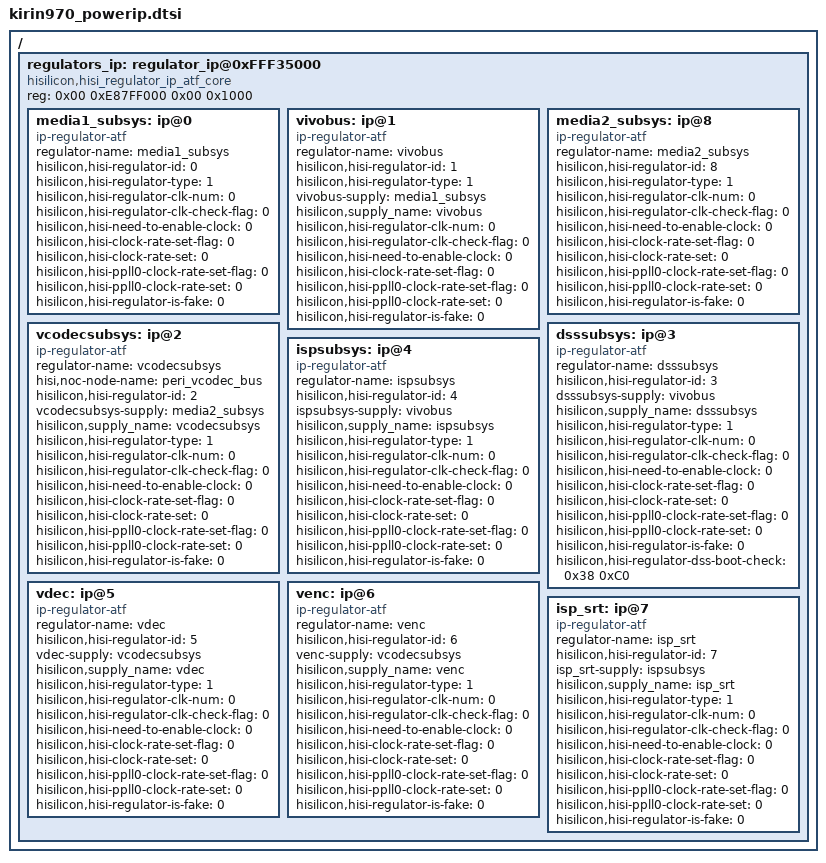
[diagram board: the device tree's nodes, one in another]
/*
 *  Copyright (C) 2012-2013 Linaro Ltd.
 *
 *  This program is free software; you can redistribute it and/or modify
 *  it under the terms of the GNU General Public License version 2 as
 *  publishhed by the Free Software Foundation.
 */

/{
	regulators_ip: regulator_ip@0xFFF35000 {
		compatible = "hisilicon,hisi_regulator_ip_atf_core";
		reg = <0x00 0xE87FF000 0x00 0x1000>;

		media1_subsys: ip@0 {
			compatible = "ip-regulator-atf";
			regulator-name = "media1_subsys";
			hisilicon,hisi-regulator-id = <0>;
			hisilicon,hisi-regulator-type = <1>;/*0:pmu;1:ip;2:scharger*/
			hisilicon,hisi-regulator-clk-num = <0>;
			hisilicon,hisi-regulator-clk-check-flag = <0>;/*0:not check clock state;1:check clock state*/
			hisilicon,hisi-need-to-enable-clock = <0>;/*0:donot enable clock;1:enable clock*/
			hisilicon,hisi-clock-rate-set-flag = <0>;/*low frequency clock set flag:0:donot set clock rate;1:set clock rate*/
			hisilicon,hisi-clock-rate-set = <0>;/*frequency:0:not set frequency;*/
			hisilicon,hisi-ppll0-clock-rate-set-flag = <0>;/*switch to ppll0 flag:0:donot set clock rate;1:set clock rate*/
			hisilicon,hisi-ppll0-clock-rate-set = <0>;/*ppll0 frequency:0:not set frequency;*/
			hisilicon,hisi-regulator-is-fake = <0>;/*0:this ip is effective;1:this ip is ineffective*/
		};
		vivobus: ip@1 {
			compatible = "ip-regulator-atf";
			regulator-name = "vivobus";
			hisilicon,hisi-regulator-id = <1>;
			hisilicon,hisi-regulator-type = <1>;/*0:pmu;1:ip;2:scharger*/
			vivobus-supply = <&media1_subsys>;
			hisilicon,supply_name = "vivobus";
			hisilicon,hisi-regulator-clk-num = <0>;
			hisilicon,hisi-regulator-clk-check-flag = <0>;/*0:not check clock state;1:check clock state*/
			hisilicon,hisi-need-to-enable-clock = <0>;/*0:donot enable clock;1:enable clock*/
			hisilicon,hisi-clock-rate-set-flag = <0>;/*low frequency clock set flag:0:donot set clock rate;1:set clock rate*/
			hisilicon,hisi-ppll0-clock-rate-set-flag = <0>;
			hisilicon,hisi-ppll0-clock-rate-set = <0>;
			hisilicon,hisi-regulator-is-fake = <0>;/*0:this ip is effective;1:this ip is ineffective*/
		};

		media2_subsys: ip@8 {
			compatible = "ip-regulator-atf";
			regulator-name = "media2_subsys";
			hisilicon,hisi-regulator-id = <8>;
			hisilicon,hisi-regulator-type = <1>;
			hisilicon,hisi-regulator-clk-num = <0>;
			hisilicon,hisi-regulator-clk-check-flag = <0>;
			hisilicon,hisi-need-to-enable-clock = <0>;
			hisilicon,hisi-clock-rate-set-flag = <0>;
			hisilicon,hisi-clock-rate-set = <0>;
			hisilicon,hisi-ppll0-clock-rate-set-flag = <0>;
			hisilicon,hisi-ppll0-clock-rate-set = <0>;
			hisilicon,hisi-regulator-is-fake = <0>;
		};

		vcodecsubsys: ip@2 {
			compatible = "ip-regulator-atf";
			regulator-name = "vcodecsubsys";
			hisi,noc-node-name = "peri_vcodec_bus";
			hisilicon,hisi-regulator-id = <2>;
			vcodecsubsys-supply = <&media2_subsys>;
			hisilicon,supply_name = "vcodecsubsys";
			hisilicon,hisi-regulator-type = <1>;
			hisilicon,hisi-regulator-clk-num = <0>;
			hisilicon,hisi-regulator-clk-check-flag = <0>;
			hisilicon,hisi-need-to-enable-clock = <0>;
			hisilicon,hisi-clock-rate-set-flag = <0>;
			hisilicon,hisi-clock-rate-set = <0>;
			hisilicon,hisi-ppll0-clock-rate-set-flag = <0>;
			hisilicon,hisi-ppll0-clock-rate-set = <0>;
			hisilicon,hisi-regulator-is-fake = <0>;
		};
		dsssubsys: ip@3 {
			compatible = "ip-regulator-atf";
			regulator-name = "dsssubsys";
			hisilicon,hisi-regulator-id = <3>;
			dsssubsys-supply = <&vivobus>;
			hisilicon,supply_name = "dsssubsys";
			hisilicon,hisi-regulator-type = <1>;
			hisilicon,hisi-regulator-clk-num = <0>;
			hisilicon,hisi-regulator-clk-check-flag = <0>;
			hisilicon,hisi-need-to-enable-clock = <0>;
			hisilicon,hisi-clock-rate-set-flag = <0>;
			hisilicon,hisi-clock-rate-set = <0>;
			hisilicon,hisi-ppll0-clock-rate-set-flag = <0>;
			hisilicon,hisi-ppll0-clock-rate-set = <0>;
			hisilicon,hisi-regulator-is-fake = <0>;
			hisilicon,hisi-regulator-dss-boot-check = <0x38 0xC0>;
		};
		ispsubsys: ip@4 {
			compatible = "ip-regulator-atf";
			regulator-name = "ispsubsys";
			hisilicon,hisi-regulator-id = <4>;
			ispsubsys-supply = <&vivobus>;
			hisilicon,supply_name = "ispsubsys";
			hisilicon,hisi-regulator-type = <1>;
			hisilicon,hisi-regulator-clk-num = <0>;
			hisilicon,hisi-regulator-clk-check-flag = <0>;
			hisilicon,hisi-need-to-enable-clock = <0>;
			hisilicon,hisi-clock-rate-set-flag = <0>;
			hisilicon,hisi-clock-rate-set = <0>;
			hisilicon,hisi-ppll0-clock-rate-set-flag = <0>;
			hisilicon,hisi-ppll0-clock-rate-set = <0>;
			hisilicon,hisi-regulator-is-fake = <0>;
		};
		vdec: ip@5 {
			compatible = "ip-regulator-atf";
			regulator-name = "vdec";
			hisilicon,hisi-regulator-id = <5>;
			vdec-supply = <&vcodecsubsys>;
			hisilicon,supply_name = "vdec";
			hisilicon,hisi-regulator-type = <1>;
			hisilicon,hisi-regulator-clk-num = <0>;
			hisilicon,hisi-regulator-clk-check-flag = <0>;
			hisilicon,hisi-need-to-enable-clock = <0>;
			hisilicon,hisi-clock-rate-set-flag = <0>;
			hisilicon,hisi-clock-rate-set = <0>;
			hisilicon,hisi-ppll0-clock-rate-set-flag = <0>;
			hisilicon,hisi-ppll0-clock-rate-set = <0>;
			hisilicon,hisi-regulator-is-fake = <0>;
		};
		venc: ip@6 {
			compatible = "ip-regulator-atf";
			regulator-name = "venc";
			hisilicon,hisi-regulator-id = <6>;
			venc-supply = <&vcodecsubsys>;
			hisilicon,supply_name = "venc";
			hisilicon,hisi-regulator-type = <1>;
			hisilicon,hisi-regulator-clk-num = <0>;
			hisilicon,hisi-regulator-clk-check-flag = <0>;
			hisilicon,hisi-need-to-enable-clock = <0>;
			hisilicon,hisi-clock-rate-set-flag = <0>;
			hisilicon,hisi-clock-rate-set = <0>;
			hisilicon,hisi-ppll0-clock-rate-set-flag = <0>;
			hisilicon,hisi-ppll0-clock-rate-set = <0>;
			hisilicon,hisi-regulator-is-fake = <0>;
		};
		isp_srt: ip@7 {
			compatible = "ip-regulator-atf";
			regulator-name = "isp_srt";
			hisilicon,hisi-regulator-id = <7>;
			isp_srt-supply = <&ispsubsys>;
			hisilicon,supply_name = "isp_srt";
			hisilicon,hisi-regulator-type = <1>;
			hisilicon,hisi-regulator-clk-num = <0>;
			hisilicon,hisi-regulator-clk-check-flag = <0>;
			hisilicon,hisi-need-to-enable-clock = <0>;
			hisilicon,hisi-clock-rate-set-flag = <0>;
			hisilicon,hisi-clock-rate-set = <0>;
			hisilicon,hisi-ppll0-clock-rate-set-flag = <0>;
			hisilicon,hisi-ppll0-clock-rate-set = <0>;
			hisilicon,hisi-regulator-is-fake = <0>;
		};
	};
};
